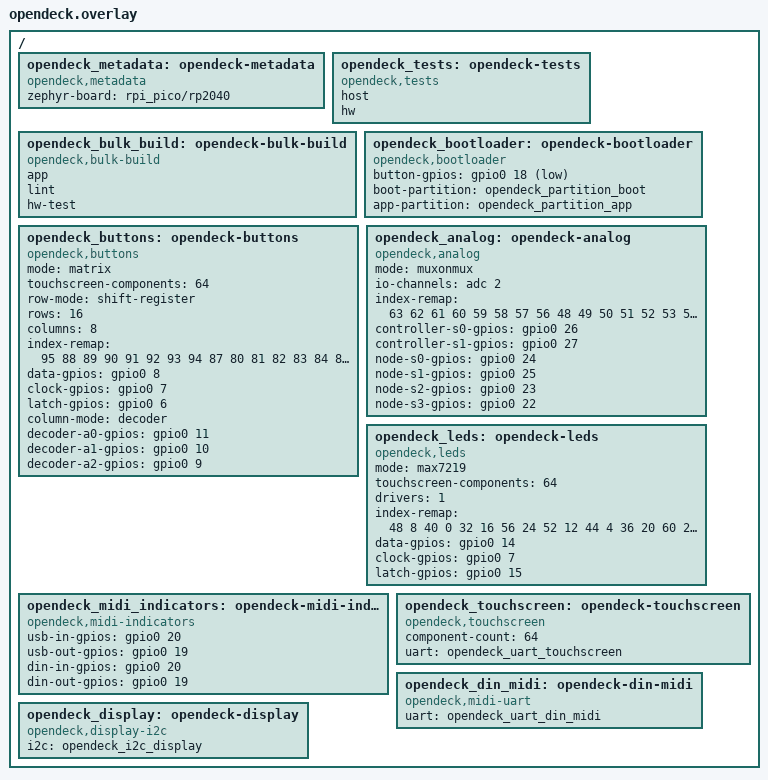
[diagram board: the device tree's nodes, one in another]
/ {
    opendeck_metadata: opendeck-metadata {
        compatible = "opendeck,metadata";
        zephyr-board = "rpi_pico/rp2040";
    };

    opendeck_tests: opendeck-tests {
        compatible = "opendeck,tests";
        host;
        hw;
    };

    opendeck_bulk_build: opendeck-bulk-build {
        compatible = "opendeck,bulk-build";
        app;
        lint;
        hw-test;
    };

    opendeck_bootloader: opendeck-bootloader {
        compatible = "opendeck,bootloader";
        button-gpios = <&gpio0 18 (GPIO_ACTIVE_LOW | GPIO_PULL_UP)>;
        boot-partition = <&opendeck_partition_boot>;
        app-partition = <&opendeck_partition_app>;
    };

    opendeck_buttons: opendeck-buttons {
        compatible = "opendeck,buttons";
        mode = "matrix";
        touchscreen-components = <64>;
        row-mode = "shift-register";
        rows = <16>;
        columns = <8>;
        index-remap = <95 88 89 90 91 92 93 94 87 80 81 82 83 84 85 86
                     79 72 73 74 75 76 77 78 71 64 65 66 67 68 69 70
                     103 96 97 98 99 100 101 102 111 104 105 106 107 108 109 110
                     119 112 113 114 115 116 117 118 127 120 121 122 123 124 125 126
                     31 24 25 26 27 28 29 30 23 16 17 18 19 20 21 22
                     15 8 9 10 11 12 13 14 7 0 1 2 3 4 5 6
                     39 32 33 34 35 36 37 38 47 40 41 42 43 44 45 46
                     55 48 49 50 51 52 53 54 63 56 57 58 59 60 61 62>;
        data-gpios = <&gpio0 8 GPIO_ACTIVE_HIGH>;
        clock-gpios = <&gpio0 7 GPIO_ACTIVE_HIGH>;
        latch-gpios = <&gpio0 6 GPIO_ACTIVE_HIGH>;
        column-mode = "decoder";
        decoder-a0-gpios = <&gpio0 11 GPIO_ACTIVE_HIGH>;
        decoder-a1-gpios = <&gpio0 10 GPIO_ACTIVE_HIGH>;
        decoder-a2-gpios = <&gpio0 9 GPIO_ACTIVE_HIGH>;
    };

    opendeck_analog: opendeck-analog {
        compatible = "opendeck,analog";
        mode = "muxonmux";
        io-channels = <&adc 2>;
        index-remap = <63 62 61 60 59 58 57 56 48 49 50 51 52 53 54 55
                     15 14 13 12 11 10 9 8 0 1 2 3 4 5 6 7
                     31 30 29 28 27 26 25 24 16 17 18 19 20 21 22 23
                     47 46 45 44 43 42 41 40 32 33 34 35 36 37 38 39>;
        controller-s0-gpios = <&gpio0 26 GPIO_ACTIVE_HIGH>;
        controller-s1-gpios = <&gpio0 27 GPIO_ACTIVE_HIGH>;
        node-s0-gpios = <&gpio0 24 GPIO_ACTIVE_HIGH>;
        node-s1-gpios = <&gpio0 25 GPIO_ACTIVE_HIGH>;
        node-s2-gpios = <&gpio0 23 GPIO_ACTIVE_HIGH>;
        node-s3-gpios = <&gpio0 22 GPIO_ACTIVE_HIGH>;
    };

    opendeck_leds: opendeck-leds {
        compatible = "opendeck,leds";
        mode = "max7219";
        touchscreen-components = <64>;
        drivers = <1>;
        index-remap = <48 8 40 0 32 16 56 24 52 12 44 4 36 20 60 28
                     54 14 46 6 38 22 62 30 50 10 42 2 34 18 58 26
                     51 11 43 3 35 19 59 27 55 15 47 7 39 23 63 31
                     53 13 45 5 37 21 61 29 49 9 41 1 33 17 57 25>;
        data-gpios = <&gpio0 14 GPIO_ACTIVE_HIGH>;
        clock-gpios = <&gpio0 7 GPIO_ACTIVE_HIGH>;
        latch-gpios = <&gpio0 15 GPIO_ACTIVE_HIGH>;
    };

    opendeck_midi_indicators: opendeck-midi-indicators {
        compatible = "opendeck,midi-indicators";
        usb-in-gpios = <&gpio0 20 GPIO_ACTIVE_HIGH>;
        usb-out-gpios = <&gpio0 19 GPIO_ACTIVE_HIGH>;
        din-in-gpios = <&gpio0 20 GPIO_ACTIVE_HIGH>;
        din-out-gpios = <&gpio0 19 GPIO_ACTIVE_HIGH>;
    };

    opendeck_touchscreen: opendeck-touchscreen {
        compatible = "opendeck,touchscreen";
        component-count = <64>;
        uart = <&opendeck_uart_touchscreen>;
    };

    opendeck_din_midi: opendeck-din-midi {
        compatible = "opendeck,midi-uart";
        uart = <&opendeck_uart_din_midi>;
    };

    opendeck_display: opendeck-display {
        compatible = "opendeck,display-i2c";
        i2c = <&opendeck_i2c_display>;
    };
};
